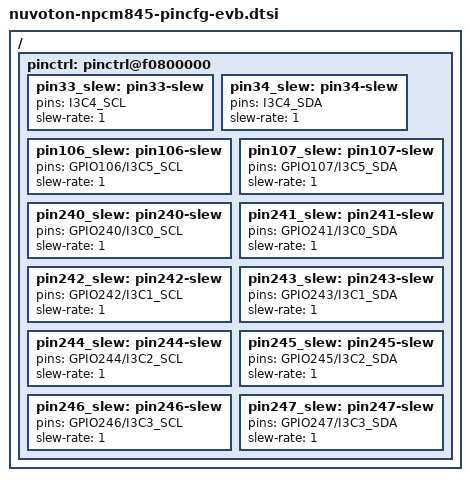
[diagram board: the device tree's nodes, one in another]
// SPDX-License-Identifier: GPL-2.0
// Copyright (c) 2018 Nuvoton Technology

/ {
	pinctrl: pinctrl@f0800000 {
		pin33_slew: pin33-slew {
			pins = "I3C4_SCL";
			slew-rate = <1>;
		};
		pin34_slew: pin34-slew {
			pins = "I3C4_SDA";
			slew-rate = <1>;
		};
		pin106_slew: pin106-slew {
			pins = "GPIO106/I3C5_SCL";
			slew-rate = <1>;
		};
		pin107_slew: pin107-slew {
			pins = "GPIO107/I3C5_SDA";
			slew-rate = <1>;
		};
		pin240_slew: pin240-slew {
			pins = "GPIO240/I3C0_SCL";
			slew-rate = <1>;
		};
		pin241_slew: pin241-slew {
			pins = "GPIO241/I3C0_SDA";
			slew-rate = <1>;
		};
		pin242_slew: pin242-slew {
			pins = "GPIO242/I3C1_SCL";
			slew-rate = <1>;
		};
		pin243_slew: pin243-slew {
			pins = "GPIO243/I3C1_SDA";
			slew-rate = <1>;
		};
		pin244_slew: pin244-slew {
			pins = "GPIO244/I3C2_SCL";
			slew-rate = <1>;
		};
		pin245_slew: pin245-slew {
			pins = "GPIO245/I3C2_SDA";
			slew-rate = <1>;
		};
		pin246_slew: pin246-slew {
			pins = "GPIO246/I3C3_SCL";
			slew-rate = <1>;
		};
		pin247_slew: pin247-slew {
			pins = "GPIO247/I3C3_SDA";
			slew-rate = <1>;
		};
	};
};
